# CH32V407 register map
Vendor: WCH Ltd.; File version: 1.0
Registers are 32-bit, read-write, reset 0x0 unless marked. A register's access mark holds for its fields unless they carry their own. Offsets are from the block's base; [hi:lo] are bit positions.

## LTDC — LCD-TFT Controller
Base 0x40024800
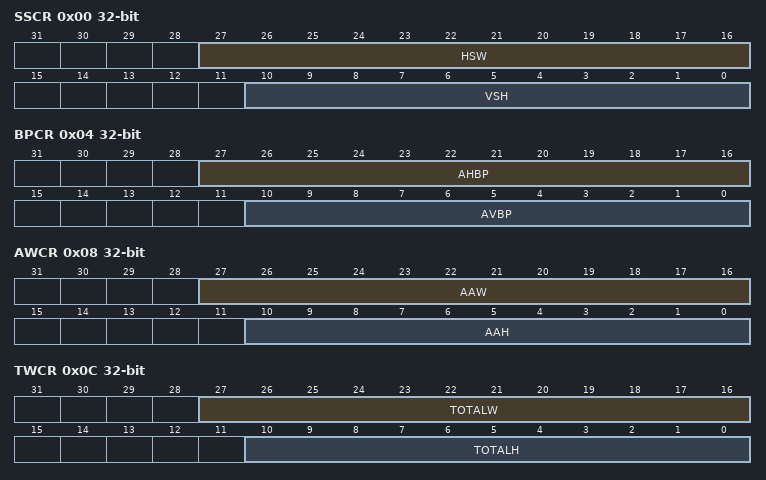
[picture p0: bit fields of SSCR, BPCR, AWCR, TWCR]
0x00 SSCR — Synchronization Size Configuration Register
  [27:16] HSW — Horizontal Synchronization Width (in units of pixel clock period)
  [10:0] VSH — Vertical Synchronization Height (in units of horizontal scan line)
0x04 BPCR — Back Porch Configuration Register
  [27:16] AHBP — Accumulated Horizontal back porch (in units of pixel clock period)
  [10:0] AVBP — Accumulated Vertical back porch (in units of horizontal scan line)
0x08 AWCR — Active Width Configuration Register
  [27:16] AAW — Accumulated Active Width (in units of pixel clock period)
  [10:0] AAH — Accumulated Active Height (in units of horizontal scan line)
0x0C TWCR — Total Width Configuration Register
  [27:16] TOTALW — Total Width (in units of pixel clock period)
  [10:0] TOTALH — Total Height (in units of horizontal scan line)
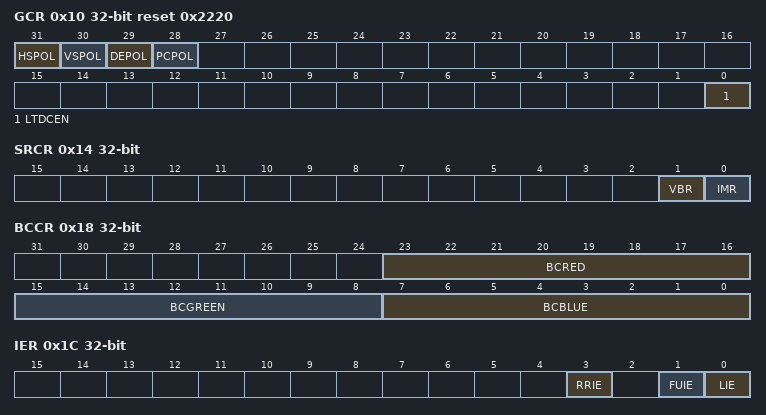
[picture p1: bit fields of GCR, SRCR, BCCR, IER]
0x10 GCR reset 0x2220 — Global Control Register
  [31] HSPOL — Horizontal Synchronization Polarity
  [30] VSPOL — Vertical Synchronization Polarity
  [29] DEPOL — Data Enable Polarity
  [28] PCPOL — Pixel Clock Polarity
  [0] LTDCEN — LCD-TFT controller enable bit
0x14 SRCR — Shadow Reload Configuration Register
  [1] VBR — Vertical Blanking Reload
  [0] IMR — Immediate Reload
0x18 BCCR — Background Color Configuration Register
  [23:16] BCRED — Background Color Red value
  [15:8] BCGREEN — Background Color Green value
  [7:0] BCBLUE — Background Color Blue value
0x1C IER — Interrupt Enable Register
  [3] RRIE — Register Reload interrupt enable
  [1] FUIE — FIFO Underrun Interrupt Enable
  [0] LIE — Line Interrupt Enable
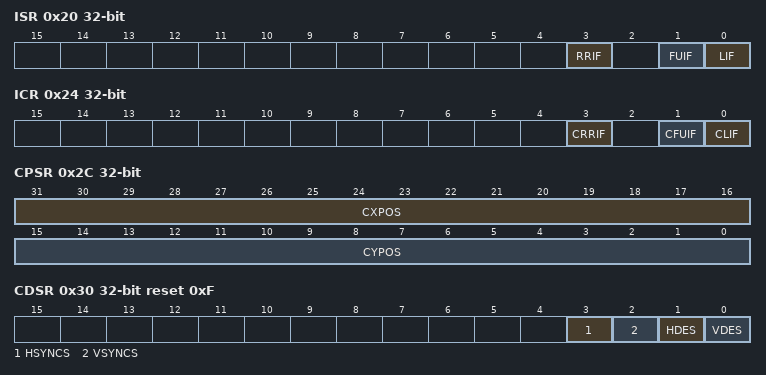
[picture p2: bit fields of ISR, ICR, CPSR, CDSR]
0x20 ISR ro — Interrupt Status Register
  [3] RRIF — Register Reload Interrupt Flag
  [1] FUIF — FIFO Underrun Interrupt flag
  [0] LIF — Line Interrupt flag
0x24 ICR wo — Interrupt Clear Register
  [3] CRRIF — Clears Register Reload Interrupt Flag
  [1] CFUIF — Clears the FIFO Underrun Interrupt flag
  [0] CLIF — Clears the Line Interrupt Flag
0x28 LIPCR — Line Interrupt Position Configuration Register
  [10:0] LIPOS — Line Interrupt Position
0x2C CPSR — Current Position Status Register
  [31:16] CXPOS — Current X Position
  [15:0] CYPOS — Current Y Position
0x30 CDSR ro reset 0xF — Current Display Status Register
  [3] HSYNCS — Horizontal Synchronization display Status
  [2] VSYNCS — Vertical Synchronization display Status
  [1] HDES — Horizontal Data Enable display Status
  [0] VDES — Vertical Data Enable display Status
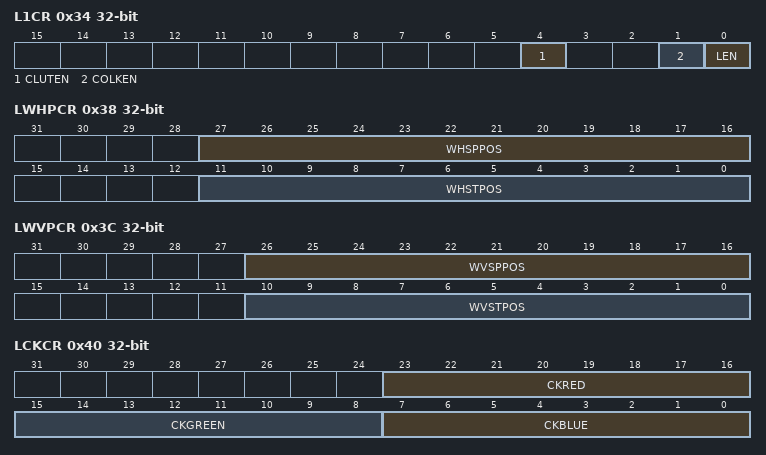
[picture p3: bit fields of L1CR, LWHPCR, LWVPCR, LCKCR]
0x34 L1CR — Layerx Control Register
  [4] CLUTEN — Color Look-Up Table Enable
  [1] COLKEN — Color Keying Enable
  [0] LEN — Layer Enable
0x38 LWHPCR — Layerx Window Horizontal Position Configuration Register
  [27:16] WHSPPOS — Window Horizontal Stop Position
  [11:0] WHSTPOS — Window Horizontal Start Position
0x3C LWVPCR — Layerx Window Vertical Position Configuration Register
  [26:16] WVSPPOS — Window Vertical Stop Position
  [10:0] WVSTPOS — Window Vertical Start Position
0x40 LCKCR — Layerx Color Keying Configuration Register
  [23:16] CKRED — Color Key Red value
  [15:8] CKGREEN — Color Key Green value
  [7:0] CKBLUE — Color Key Blue value
0x44 LPFCR — Layerx Pixel Format Configuration Register
  [2:0] PF — Pixel Format
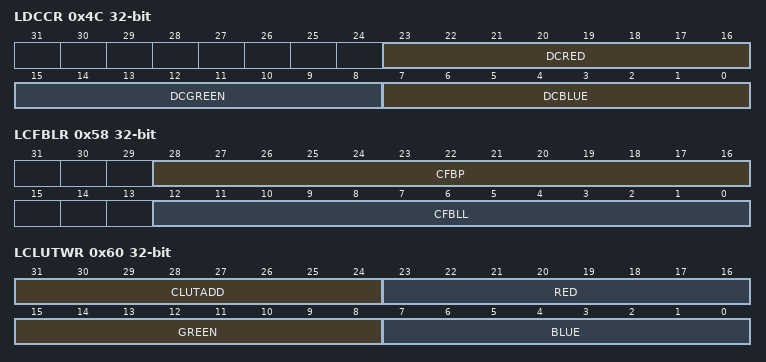
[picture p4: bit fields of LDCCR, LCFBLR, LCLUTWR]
0x4C LDCCR — Layerx Default Color Configuration Register
  [23:16] DCRED — Default Color Red
  [15:8] DCGREEN — Default Color Green
  [7:0] DCBLUE — Default Color Blue
0x54 LCFBAR — Layerx Color Frame Buffer Address Register
  [31:0] CFBADD — Color Frame Buffer Start Address
0x58 LCFBLR — Layerx Color Frame Buffer Length Register
  [28:16] CFBP — Color Frame Buffer Pitch in bytes
  [12:0] CFBLL — Color Frame Buffer Line Length
0x5C LCFBLNR — Layerx ColorFrame Buffer Line Number Register
  [10:0] CFBLNBR — Frame Buffer Line Number
0x60 LCLUTWR wo — Layerx CLUT Write Register
  [31:24] CLUTADD — CLUT Address
  [23:16] RED — Red value
  [15:8] GREEN — Green value
  [7:0] BLUE — Blue value
